# STM32L052 register map
File version: 1.0
CPU: CM0+ r0p0, little endian, MPU, no FPU, 4 interrupt priority bits
Registers are 32-bit, read-write, reset 0x0 unless marked. A register's access mark holds for its fields unless they carry their own. Offsets are from the block's base; [hi:lo] are bit positions.

## SPI1 — Serial peripheral interface
Base 0x40013000
Same registers: SPI2 0x40003800
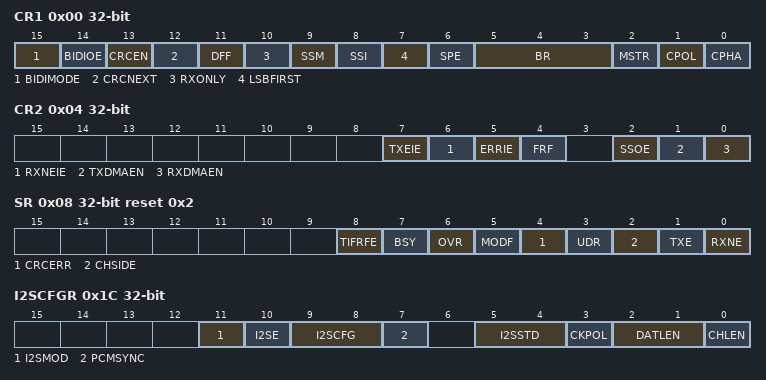
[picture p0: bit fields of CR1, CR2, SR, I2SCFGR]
0x00 CR1 — control register 1
  [15] BIDIMODE — Bidirectional data mode enable
  [14] BIDIOE — Output enable in bidirectional mode
  [13] CRCEN — Hardware CRC calculation enable
  [12] CRCNEXT — CRC transfer next
  [11] DFF — Data frame format
  [10] RXONLY — Receive only
  [9] SSM — Software slave management
  [8] SSI — Internal slave select
  [7] LSBFIRST — Frame format
  [6] SPE — SPI enable
  [5:3] BR — Baud rate control
  [2] MSTR — Master selection
  [1] CPOL — Clock polarity
  [0] CPHA — Clock phase
0x04 CR2 — control register 2
  [7] TXEIE — Tx buffer empty interrupt enable
  [6] RXNEIE — RX buffer not empty interrupt enable
  [5] ERRIE — Error interrupt enable
  [4] FRF — Frame format
  [2] SSOE — SS output enable
  [1] TXDMAEN — Tx buffer DMA enable
  [0] RXDMAEN — Rx buffer DMA enable
0x08 SR access per field reset 0x2 — status register
  [8] TIFRFE ro — TI frame format error
  [7] BSY ro — Busy flag
  [6] OVR ro — Overrun flag
  [5] MODF ro — Mode fault
  [4] CRCERR rw — CRC error flag
  [3] UDR ro — Underrun flag
  [2] CHSIDE ro — Channel side
  [1] TXE ro — Transmit buffer empty
  [0] RXNE ro — Receive buffer not empty
0x0C DR — data register
  [15:0] DR — Data register
0x10 CRCPR reset 0x7 — CRC polynomial register
  [15:0] CRCPOLY
0x14 RXCRCR ro — RX CRC register
  [15:0] RxCRC
0x18 TXCRCR ro — TX CRC register
  [15:0] TxCRC
0x1C I2SCFGR — I2S configuration register
  [11] I2SMOD — I2S mode selection
  [10] I2SE — I2S Enable
  [9:8] I2SCFG — I2S configuration mode
  [7] PCMSYNC — PCM frame synchronization
  [5:4] I2SSTD — I2S standard selection
  [3] CKPOL — Steady state clock polarity
  [2:1] DATLEN — Data length to be transferred
  [0] CHLEN — Channel length (number of bits per audio channel)
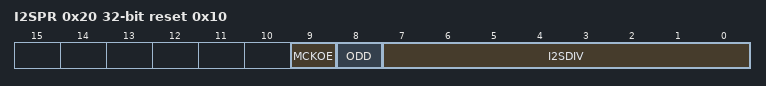
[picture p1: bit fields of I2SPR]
0x20 I2SPR reset 0x10 — I2S prescaler register
  [9] MCKOE — Master clock output enable
  [8] ODD — Odd factor for the prescaler
  [7:0] I2SDIV — I2S Linear prescaler

## TIM6 — Basic-timers
Base 0x40001000
Same registers: TIM7 0x40001400
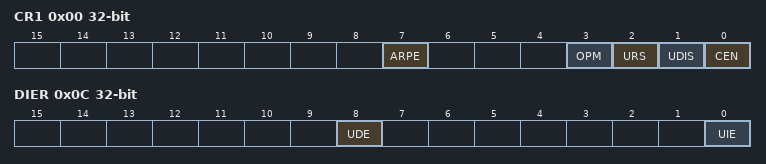
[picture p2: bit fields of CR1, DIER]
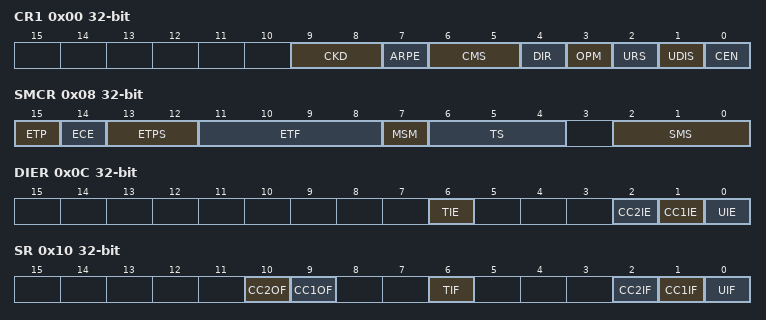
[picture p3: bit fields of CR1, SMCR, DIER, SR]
0x00 CR1 — control register 1
  [7] ARPE — Auto-reload preload enable
  [3] OPM — One-pulse mode
  [2] URS — Update request source
  [1] UDIS — Update disable
  [0] CEN — Counter enable
0x04 CR2 — control register 2
  [6:4] MMS — Master mode selection
0x0C DIER — DMA/Interrupt enable register
  [8] UDE — Update DMA request enable
  [0] UIE — Update interrupt enable
0x10 SR — status register
  [0] UIF — Update interrupt flag
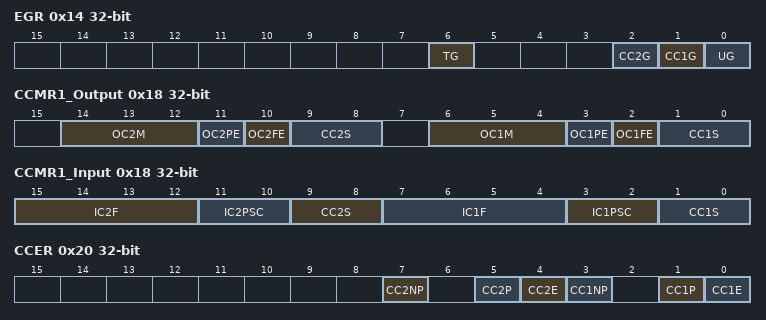
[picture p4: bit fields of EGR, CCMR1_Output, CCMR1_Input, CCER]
0x14 EGR wo — event generation register
  [0] UG — Update generation
0x24 CNT — counter
  [15:0] CNT — Low counter value
0x28 PSC — prescaler
  [15:0] PSC — Prescaler value
0x2C ARR — auto-reload register
  [15:0] ARR — Low Auto-reload value

## TIM21 — General-purpose-timers
Base 0x40010800
0x00 CR1 — control register 1
  [9:8] CKD — Clock division
  [7] ARPE — Auto-reload preload enable
  [6:5] CMS — Center-aligned mode selection
  [4] DIR — Direction
  [3] OPM — One-pulse mode
  [2] URS — Update request source
  [1] UDIS — Update disable
  [0] CEN — Counter enable
0x04 CR2 — control register 2
  [6:4] MMS — Master mode selection
0x08 SMCR — slave mode control register
  [15] ETP — External trigger polarity
  [14] ECE — External clock enable
  [13:12] ETPS — External trigger prescaler
  [11:8] ETF — External trigger filter
  [7] MSM — Master/Slave mode
  [6:4] TS — Trigger selection
  [2:0] SMS — Slave mode selection
0x0C DIER — DMA/Interrupt enable register
  [6] TIE — Trigger interrupt enable
  [2] CC2IE — Capture/Compare 2 interrupt enable
  [1] CC1IE — Capture/Compare 1 interrupt enable
  [0] UIE — Update interrupt enable
0x10 SR — status register
  [10] CC2OF — Capture/compare 2 overcapture flag
  [9] CC1OF — Capture/Compare 1 overcapture flag
  [6] TIF — Trigger interrupt flag
  [2] CC2IF — Capture/Compare 2 interrupt flag
  [1] CC1IF — Capture/compare 1 interrupt flag
  [0] UIF — Update interrupt flag
0x14 EGR wo — event generation register
  [6] TG — Trigger generation
  [2] CC2G — Capture/compare 2 generation
  [1] CC1G — Capture/compare 1 generation
  [0] UG — Update generation
0x18 CCMR1_Output — capture/compare mode register (output mode)
  [14:12] OC2M — Output Compare 2 mode
  [11] OC2PE — Output Compare 2 preload enable
  [10] OC2FE — Output Compare 2 fast enable
  [9:8] CC2S — Capture/Compare 2 selection
  [6:4] OC1M — Output Compare 1 mode
  [3] OC1PE — Output Compare 1 preload enable
  [2] OC1FE — Output Compare 1 fast enable
  [1:0] CC1S — Capture/Compare 1 selection
0x18 CCMR1_Input (alternate view of CCMR1_Output) — capture/compare mode register 1 (input mode)
  [15:12] IC2F — Input capture 2 filter
  [11:10] IC2PSC — Input capture 2 prescaler
  [9:8] CC2S — Capture/Compare 2 selection
  [7:4] IC1F — Input capture 1 filter
  [3:2] IC1PSC — Input capture 1 prescaler
  [1:0] CC1S — Capture/Compare 1 selection
0x20 CCER — capture/compare enable register
  [7] CC2NP — Capture/Compare 2 output Polarity
  [5] CC2P — Capture/Compare 2 output Polarity
  [4] CC2E — Capture/Compare 2 output enable
  [3] CC1NP — Capture/Compare 1 output Polarity
  [1] CC1P — Capture/Compare 1 output Polarity
  [0] CC1E — Capture/Compare 1 output enable
0x24 CNT — counter
  [15:0] CNT — counter value
0x28 PSC — prescaler
  [15:0] PSC — Prescaler value
0x2C ARR — auto-reload register
  [15:0] ARR — Auto-reload value
0x34 CCR1 — capture/compare register 1
  [15:0] CCR1 — Capture/Compare 1 value
0x38 CCR2 — capture/compare register 2
  [15:0] CCR2 — Capture/Compare 2 value
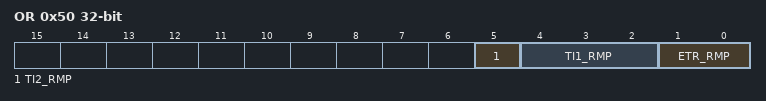
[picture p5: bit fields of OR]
0x50 OR — TIM21 option register
  [5] TI2_RMP — Timer21 TI2
  [4:2] TI1_RMP — Timer21 TI1
  [1:0] ETR_RMP — Timer21 ETR remap

## TIM22 — General-purpose-timers
Base 0x40011400
Registers as TIM21; these are added or differ:
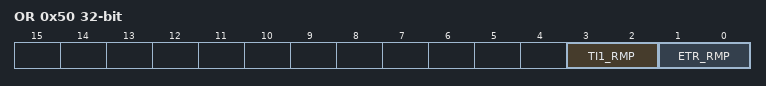
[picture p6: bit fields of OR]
0x50 OR — TIM22 option register
  [3:2] TI1_RMP — Timer22 TI1
  [1:0] ETR_RMP — Timer22 ETR remap
